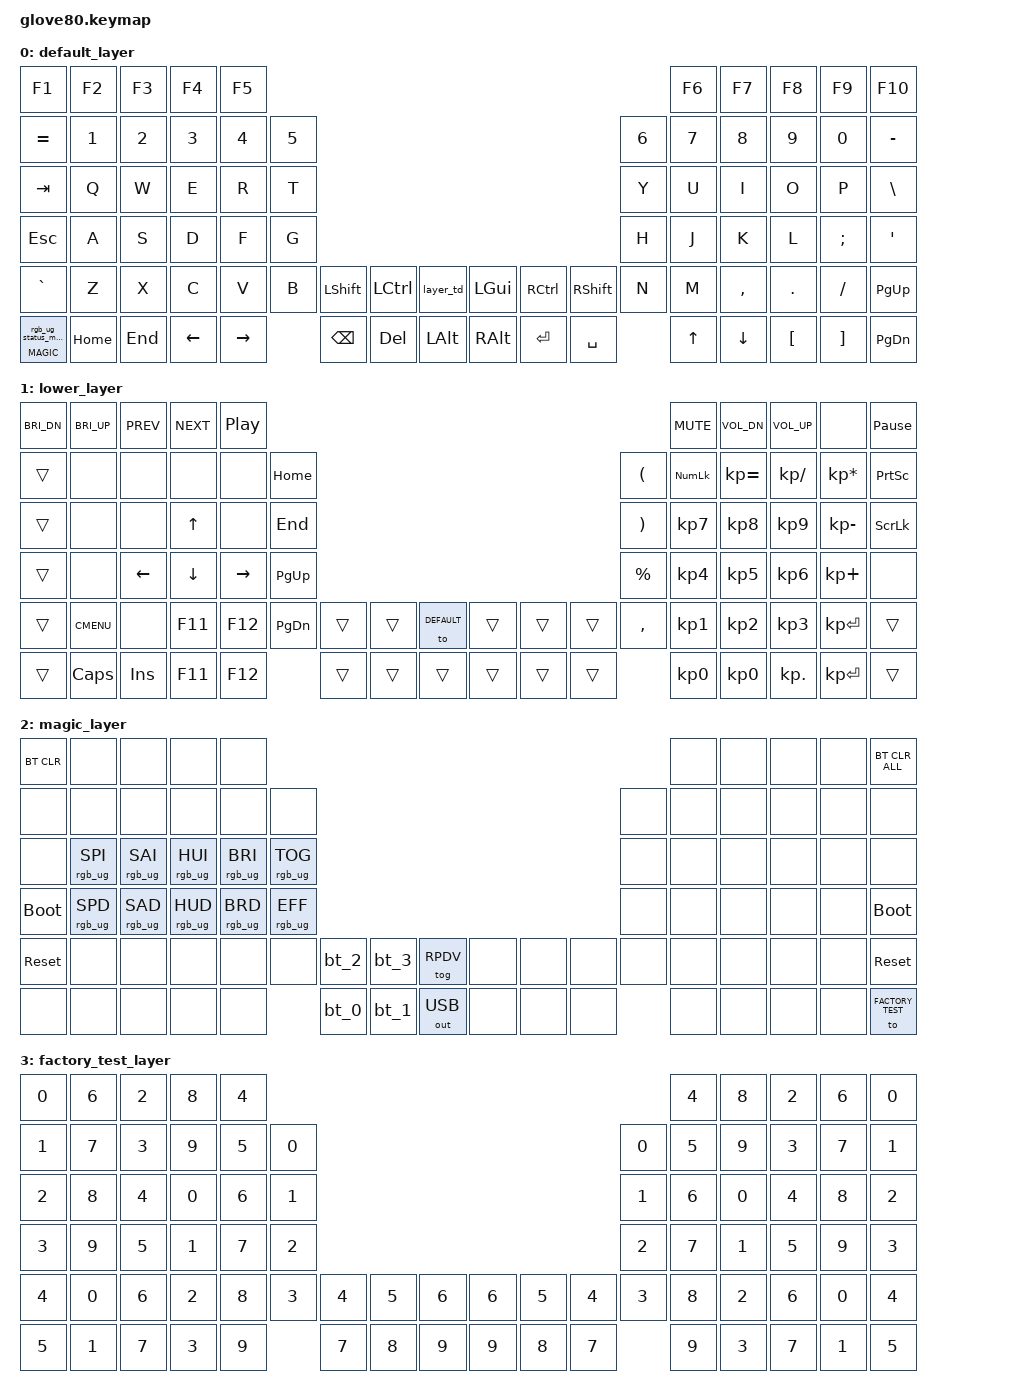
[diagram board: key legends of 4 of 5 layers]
/*
 * Copyright (c) 2020 The ZMK Contributors
 *
 * SPDX-License-Identifier: MIT
 */

#include <behaviors.dtsi>
#include <dt-bindings/zmk/keys.h>
#include <dt-bindings/zmk/bt.h>
#include <dt-bindings/zmk/ext_power.h>
#include <dt-bindings/zmk/outputs.h>
#include <dt-bindings/zmk/rgb.h>

#include "keyhelpers.h"
#define KEYS_L LT0 LT1 LT2 LT3 LT4 LT5 \
               LM0 LM1 LM2 LM3 LM4 LM5 \
               LB0 LB1 LB2 LB3 LB4 LB5
#define KEYS_R RT0 RT1 RT2 RT3 RT4 RT5 \
               RM0 RM1 RM2 RM3 RM4 RM5 \
               RB0 RB1 RB2 RB3 RB4 RB5
#define PERIPH LH0 LH1 LH2 LH3 LH4 LH5 RH0 RH1 RH2 RH3 RH4 RH5 \
               LC1 LC2 LC3 LC4 LC5 RC1 RC2 RC3 RC4 RC5 \
               LN1 LN2 LN3 LN4 LN5 RN1 RN2 RN3 RN4 RN5 \
                   LF2 LF3 LF4 LF5 RF1 RF2 RF3 RF4 RF5

#define HYPER LC(LS(LG(LALT)))

// layers
#define DEFAULT 0
#define LOWER 1
#define MAGIC 2
#define FACTORY_TEST 3
#define RPDV 4

/ {
    behaviors {
        // For the "layer" key, it'd nice to be able to use it as either a shift or a toggle.
        // Configure it as a tap dance, so the first tap (or hold) is a &mo and the second tap is a &to
        layer_td: tap_dance_0 {
            compatible = "zmk,behavior-tap-dance";
            label = "LAYER_TAP_DANCE";
            #binding-cells = <0>;
            tapping-term-ms = <200>;
            bindings = <&mo LOWER>, <&to LOWER>;
        };

        magic: magic_hold_tap {
            compatible = "zmk,behavior-hold-tap";
            label = "MAGIC_HOLD_TAP";
            #binding-cells = <2>;
            flavor = "tap-preferred";
            tapping-term-ms = <200>;
            bindings = <&mo>, <&rgb_ug_status_macro>;
        };

        // Home-row mods
        hml: home_row_mod_left {
            compatible = "zmk,behavior-hold-tap";
            #binding-cells = <2>;
            flavor = "tap-unless-interrupted";
            tapping-term-ms = <1000>;
            bindings = <&kp>, <&kp>;
            hold-trigger-key-positions = <KEYS_R PERIPH>;
            hold-trigger-on-release;
        };

        hmr: home_row_mod_right {
            compatible = "zmk,behavior-hold-tap";
            #binding-cells = <2>;
            flavor = "tap-unless-interrupted";
            tapping-term-ms = <1000>;
            bindings = <&kp>, <&kp>;
            hold-trigger-key-positions = <KEYS_L PERIPH>;
            hold-trigger-on-release;
        };

        // Special character custom unshifted-shifted pairs
        gpipe: grave_pipe {
            compatible = "zmk,behavior-mod-morph";
            label = "grave_pipe";
            #binding-cells = <0>;
            bindings = <&kp GRAVE>, <&kp PIPE>;
            mods = <(MOD_LGUI|MOD_LSFT|MOD_RGUI|MOD_RSFT)>;
        };
        ppipe: pipe_pipe {
            compatible = "zmk,behavior-mod-morph";
            label = "pipe_pipe";
            #binding-cells = <0>;
            bindings = <&kp PIPE>, <&kp PIPE>;
            mods = <(MOD_LGUI|MOD_LSFT|MOD_RGUI|MOD_RSFT)>;
        };
        pkp_n1: plus_kp_n1 {
            compatible = "zmk,behavior-mod-morph";
            label = "plus_kp_n1";
            #binding-cells = <0>;
            bindings = <&kp PLUS>, <&kp KP_N1>;
            mods = <(MOD_LGUI|MOD_LSFT|MOD_RGUI|MOD_RSFT)>;
        };
        lkp_n2: left_bracket_kp_n2 {
            compatible = "zmk,behavior-mod-morph";
            label = "left_bracket_kp_n2";
            #binding-cells = <0>;
            bindings = <&kp LEFT_BRACKET>, <&kp KP_N2>;
            mods = <(MOD_LGUI|MOD_LSFT|MOD_RGUI|MOD_RSFT)>;
        };
        lkp_n3: left_brace_kp_n3 {
            compatible = "zmk,behavior-mod-morph";
            label = "left_brace_kp_n3";
            #binding-cells = <0>;
            bindings = <&kp LEFT_BRACE>, <&kp KP_N3>;
            mods = <(MOD_LGUI|MOD_LSFT|MOD_RGUI|MOD_RSFT)>;
        };
        lkp_n4: left_parenthesis_kp_n4 {
            compatible = "zmk,behavior-mod-morph";
            label = "left_parenthesis_kp_n4";
            #binding-cells = <0>;
            bindings = <&kp LEFT_PARENTHESIS>, <&kp KP_N4>;
            mods = <(MOD_LGUI|MOD_LSFT|MOD_RGUI|MOD_RSFT)>;
        };
        akp_n5: amps_kp_n5 {
            compatible = "zmk,behavior-mod-morph";
            label = "amps_kp_n5";
            #binding-cells = <0>;
            bindings = <&kp AMPS>, <&kp KP_N5>;
            mods = <(MOD_LGUI|MOD_LSFT|MOD_RGUI|MOD_RSFT)>;
        };
        ekp_n6: equal_kp_n6 {
            compatible = "zmk,behavior-mod-morph";
            label = "equal_kp_n6";
            #binding-cells = <0>;
            bindings = <&kp EQUAL>, <&kp KP_N6>;
            mods = <(MOD_LGUI|MOD_LSFT|MOD_RGUI|MOD_RSFT)>;
        };
        rkp_n7: right_parenthesis_kp_n7 {
            compatible = "zmk,behavior-mod-morph";
            label = "right_parenthesis_kp_n7";
            #binding-cells = <0>;
            bindings = <&kp RIGHT_PARENTHESIS>, <&kp KP_N7>;
            mods = <(MOD_LGUI|MOD_LSFT|MOD_RGUI|MOD_RSFT)>;
        };
        rkp_n8: right_brace_kp_n8 {
            compatible = "zmk,behavior-mod-morph";
            label = "right_brace_kp_n8";
            #binding-cells = <0>;
            bindings = <&kp RIGHT_BRACE>, <&kp KP_N8>;
            mods = <(MOD_LGUI|MOD_LSFT|MOD_RGUI|MOD_RSFT)>;
        };
        rkp_n9: right_bracket_kp_n9 {
            compatible = "zmk,behavior-mod-morph";
            label = "right_bracket_kp_n9";
            #binding-cells = <0>;
            bindings = <&kp RIGHT_BRACKET>, <&kp KP_N9>;
            mods = <(MOD_LGUI|MOD_LSFT|MOD_RGUI|MOD_RSFT)>;
        };
        skp_n0: star_kp_n0 {
            compatible = "zmk,behavior-mod-morph";
            label = "star_kp_n0";
            #binding-cells = <0>;
            bindings = <&kp STAR>, <&kp KP_N0>;
            mods = <(MOD_LGUI|MOD_LSFT|MOD_RGUI|MOD_RSFT)>;
        };
        eprcnt: excl_prcnt {
            compatible = "zmk,behavior-mod-morph";
            label = "excl_prcnt";
            #binding-cells = <0>;
            bindings = <&kp EXCL>, <&kp PRCNT>;
            mods = <(MOD_LGUI|MOD_LSFT|MOD_RGUI|MOD_RSFT)>;
        };

        dgrave: dllr_grave {
            compatible = "zmk,behavior-mod-morph";
            label = "dllr_grave";
            #binding-cells = <0>;
            bindings = <&kp DLLR>, <&kp GRAVE>;
            mods = <(MOD_LGUI|MOD_LSFT|MOD_RGUI|MOD_RSFT)>;
        };
        ggrave: grave_grave {
            compatible = "zmk,behavior-mod-morph";
            label = "grave_grave";
            #binding-cells = <0>;
            bindings = <&kp GRAVE>, <&kp GRAVE>;
            mods = <(MOD_LGUI|MOD_LSFT|MOD_RGUI|MOD_RSFT)>;
        };
        bhash: bslh_hash {
            compatible = "zmk,behavior-mod-morph";
            label = "bslh_hash";
            #binding-cells = <0>;
            bindings = <&kp BSLH>, <&kp HASH>;
            mods = <(MOD_LGUI|MOD_LSFT|MOD_RGUI|MOD_RSFT)>;
        };
        acaret: at_caret {
            compatible = "zmk,behavior-mod-morph";
            label = "at_caret";
            #binding-cells = <0>;
            bindings = <&kp AT>, <&kp CARET>;
            mods = <(MOD_LGUI|MOD_LSFT|MOD_RGUI|MOD_RSFT)>;
        };
    };

    macros {
        rgb_ug_status_macro: rgb_ug_status_macro_0 {
            label = "RGB_UG_STATUS";
            compatible = "zmk,behavior-macro";
            #binding-cells = <0>;
            bindings
                = <&rgb_ug RGB_STATUS>;
        };

        bt_0: bt_profile_macro_0 {
            label = "BT_0";
            compatible = "zmk,behavior-macro";
            #binding-cells = <0>;
            bindings
                = <&out OUT_BLE>,
                  <&bt BT_SEL 0>;
        };

        bt_1: bt_profile_macro_1 {
            label = "BT_1";
            compatible = "zmk,behavior-macro";
            #binding-cells = <0>;
            bindings
                = <&out OUT_BLE>,
                  <&bt BT_SEL 1>;
        };

        bt_2: bt_profile_macro_2 {
            label = "BT_2";
            compatible = "zmk,behavior-macro";
            #binding-cells = <0>;
            bindings
                = <&out OUT_BLE>,
                  <&bt BT_SEL 2>;
        };

        bt_3: bt_profile_macro_3 {
            label = "BT_3";
            compatible = "zmk,behavior-macro";
            #binding-cells = <0>;
            bindings
                = <&out OUT_BLE>,
                  <&bt BT_SEL 3>;
        };
    };

    keymap {
        compatible = "zmk,keymap";

        default_layer {
            // ---------------------------------------------------------------------------------------------------------------------------------
            // |  F1   |  F2 |  F3 |  F4  |  F5  |                                                               |  F6   |  F7   |  F8  |   F9  |  F10 |
            // |  =    |  1  |  2  |  3   |  4   |  5   |                                                 |  6   |   7   |   8   |  9   |   0   |   -  |
            // |  TAB  |  Q  |  W  |  E   |  R   |  T   |                                                 |  Y   |   U   |   I   |  O   |   P   |   \  |
            // |  ESC  |  A  |  S  |  D   |  F   |  G   |                                                 |  H   |   J   |   K   |  L   |   ;   |   '  |
            // |   `   |  Z  |  X  |  C   |  V   |  B   | LSHFT | LCTRL | LOWER | | LGUI  | RCTRL | RSHFT |  N   |   M   |   ,   |  .   |   /   | PGUP |
            // | MAGIC | HOME| END | LEFT | RIGHT|      | BSPC  | DEL   | LALT  | | RALT  | RET   | SPACE |      |  UP   | DOWN  |  [   |   ]   | PGDN |

            bindings = <
            &kp F1         &kp F2   &kp F3      &kp F4      &kp F5                                                                                         &kp F6  &kp F7      &kp F8      &kp F9      &kp F10
            &kp EQUAL      &kp N1   &kp N2      &kp N3      &kp N4      &kp N5                                                                     &kp N6  &kp N7  &kp N8      &kp N9      &kp N0      &kp MINUS
            &kp TAB        &kp Q    &kp W       &kp E       &kp R       &kp T                                                                      &kp Y   &kp U   &kp I       &kp O       &kp P       &kp BSLH
            &kp ESC        &kp A    &kp S       &kp D       &kp F       &kp G                                                                      &kp H   &kp J   &kp K       &kp L       &kp SEMI    &kp SQT
            &kp GRAVE      &kp Z    &kp X       &kp C       &kp V       &kp B   &kp LSHFT   &kp LCTRL   &layer_td  &kp LGUI  &kp RCTRL &kp RSHFT   &kp N   &kp M   &kp COMMA   &kp DOT     &kp FSLH    &kp PG_UP
            &magic MAGIC 0 &kp HOME &kp END     &kp LEFT    &kp RIGHT           &kp BSPC    &kp DEL     &kp LALT   &kp RALT  &kp RET   &kp SPACE           &kp UP  &kp DOWN    &kp LBKT    &kp RBKT    &kp PG_DN
            >;
        };

        lower_layer {
            bindings = <
            &kp C_BRI_DN      &kp C_BRI_UP        &kp C_PREV      &kp C_NEXT      &kp C_PP                                                                                                           &kp C_MUTE   &kp C_VOL_DN &kp C_VOL_UP  &none           &kp PAUSE_BREAK
            &trans            &none               &none           &none           &none           &kp HOME                                                                              &kp LPAR     &kp KP_NUM   &kp KP_EQUAL &kp KP_DIVIDE &kp KP_MULTIPLY &kp PSCRN
            &trans            &none               &none           &kp UP          &none           &kp END                                                                               &kp RPAR     &kp KP_N7    &kp KP_N8    &kp KP_N9     &kp KP_MINUS    &kp SLCK
            &trans            &none               &kp LEFT        &kp DOWN        &kp RIGHT       &kp PG_UP                                                                             &kp PRCNT    &kp KP_N4    &kp KP_N5    &kp KP_N6     &kp KP_PLUS     &none
            &trans            &kp K_CMENU         &none           &kp F11         &kp F12         &kp PG_DN       &trans      &trans      &to DEFAULT &trans      &trans      &trans    &kp COMMA    &kp KP_N1    &kp KP_N2    &kp KP_N3     &kp KP_ENTER    &trans
            &trans            &kp CAPS            &kp INS         &kp F11         &kp F12                         &trans      &trans      &trans      &trans      &trans      &trans                 &kp KP_N0    &kp KP_N0    &kp KP_DOT    &kp KP_ENTER    &trans
            >;
        };

        magic_layer {
            bindings = <
            &bt BT_CLR        &none               &none           &none           &none                                                                                                           &none      &none      &none      &none      &bt BT_CLR_ALL
            &none             &none               &none           &none           &none           &none                                                                                &none      &none      &none      &none      &none      &none
            &none             &rgb_ug RGB_SPI     &rgb_ug RGB_SAI &rgb_ug RGB_HUI &rgb_ug RGB_BRI &rgb_ug RGB_TOG                                                                      &none      &none      &none      &none      &none      &none
            &bootloader       &rgb_ug RGB_SPD     &rgb_ug RGB_SAD &rgb_ug RGB_HUD &rgb_ug RGB_BRD &rgb_ug RGB_EFF                                                                      &none      &none      &none      &none      &none      &bootloader
            &sys_reset        &none               &none           &none           &none           &none           &bt_2     &bt_3     &tog RPDV        &none     &none     &none       &none      &none      &none      &none      &none      &sys_reset
            &none             &none               &none           &none           &none                           &bt_0     &bt_1     &out OUT_USB     &none     &none     &none                  &none      &none      &none      &none      &to FACTORY_TEST
            >;
        };

        factory_test_layer {
            bindings = <
            &kp N0   &kp N6   &kp N2   &kp N8   &kp N4                                                                              &kp N4   &kp N8   &kp N2   &kp N6   &kp N0
            &kp N1   &kp N7   &kp N3   &kp N9   &kp N5   &kp N0                                                            &kp N0   &kp N5   &kp N9   &kp N3   &kp N7   &kp N1
            &kp N2   &kp N8   &kp N4   &kp N0   &kp N6   &kp N1                                                            &kp N1   &kp N6   &kp N0   &kp N4   &kp N8   &kp N2
            &kp N3   &kp N9   &kp N5   &kp N1   &kp N7   &kp N2                                                            &kp N2   &kp N7   &kp N1   &kp N5   &kp N9   &kp N3
            &kp N4   &kp N0   &kp N6   &kp N2   &kp N8   &kp N3   &kp N4   &kp N5   &kp N6      &kp N6   &kp N5   &kp N4   &kp N3   &kp N8   &kp N2   &kp N6   &kp N0   &kp N4
            &kp N5   &kp N1   &kp N7   &kp N3   &kp N9            &kp N7   &kp N8   &kp N9      &kp N9   &kp N8   &kp N7            &kp N9   &kp N3   &kp N7   &kp N1   &kp N5
            >;
        };

        real_prog_dvorak {
            // ---------------------------------------------------------------------------------------------------------------------------------
            // |  F1   |  F2 |  F3 |  F4  |  F5  |                                                               |  F6   |  F7   |  F8  |   F9  |  F10 |
            // |  |    |  +  |  [  |  {   |  (   |  &   |                                                 |  =   |   )   |   }   |  ]   |   *   |   !  |
            // |  TAB  |  ;  |  ,  |  .   |  P   |  Y   |                                                 |  F   |   G   |   C   |  R   |   L   |   \  |
            // |  ESC  |  A  |  O  |  E   |  U   |  I   |                                                 |  D   |   H   |   T   |  N   |   S   |   -  |
            // |  LSFT |  '  |  Q  |  J   |  K   |  X   | LSHFT | LCTRL | LOWER | | LGUI  | RCTRL | RSHFT |  B   |   M   |   W   |  V   |   Z   | RSFT |
            // | MAGIC |  $  |  `  | LEFT | RIGHT|      | BSPC  | DEL   | LALT  | | RALT  | RET   | SPACE |      |  UP   | DOWN  |  /   |   @   | SSRQ |

            bindings = <
            &kp F1         &kp F2   &kp F3      &kp F4        &kp F5                                                                                          &kp F6       &kp F7       &kp F8      &kp F9      &kp F10
            &ppipe         &pkp_n1  &lkp_n2     &lkp_n3       &lkp_n4      &akp_n5                                                                    &ekp_n6 &rkp_n7      &rkp_n8      &rkp_n9     &skp_n0     &eprcnt
            &kp TAB        &kp ;    &kp ,       &hml DOT LGUI &kp P        &kp Y                                                                      &kp F   &kp G        &hmr C RGUI  &kp R       &kp L       &bhash
            &kp ESC        &kp A    &hml O LALT &hml E LTCRL  &hml U LSHFT &kp I                                                                      &kp D   &hmr H RSHFT &hmr T RCTRL &hmr N RALT &kp S       &kp MINUS
            &kp LSFT       &kp APOS &kp Q       &kp J         &kp K        &kp X   &kp LSHFT   &kp LCTRL   &layer_td  &kp LGUI  &kp RCTRL &kp RSHFT   &kp B   &kp M        &kp W        &kp V       &kp Z       &kp RSFT
            &magic MAGIC 0 &kp $    &kp `       &kp LEFT      &kp RIGHT            &kp BSPC    &kp DEL     &kp LALT   &kp RALT  &kp RET   &kp SPACE           &kp UP       &kp DOWN     &kp FSLH    &acaret     &kp SSRQ
            >;
        };
    };
};
